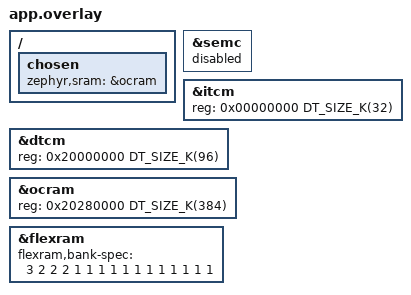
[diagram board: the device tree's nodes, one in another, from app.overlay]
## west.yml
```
manifest:
  remotes:
    - name: zephyrproject-rtos
      url-base: https://github.com/zephyrproject-rtos
  projects:
    - name: zephyr
      remote: zephyrproject-rtos
      revision: v4.4.2
      clone-depth: 1
      import: true
  self:
    path: app
```

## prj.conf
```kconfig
# Enable Zephyr Logging Framework
CONFIG_LOG=y
CONFIG_LOG_MODE_IMMEDIATE=n   # Use deferred logging mode for minimal performance impact

# Enable SEGGER RTT Core
CONFIG_USE_SEGGER_RTT=y
CONFIG_SEGGER_RTT_CUSTOM_LOCKING=y

CONFIG_LOG_BACKEND_RTT=n
CONFIG_LOG_BACKEND_UART=n    # Disable UART logging to save pins/power (optional)
CONFIG_SHELL_LOG_BACKEND=y

# Buffer size adjustments (increase if logs get dropped under high throughput)
CONFIG_SEGGER_RTT_BUFFER_SIZE_UP=2048
CONFIG_SHELL=y
CONFIG_SHELL_BACKEND_RTT=y

# Enable Zephyr's code & data relocation subsystem
# CONFIG_CODE_DATA_RELOCATION=y

# Enable Cortex-M7 instruction cache (ensures rest of XIP Flash runs at peak speed)
#CONFIG_ICACHE=y
#CONFIG_DCACHE=y

# Copy the ARM vector table into RAM (VTOR points to RAM)
# CONFIG_SRAM_VECTOR_TABLE=y

#CONFIG_SRAM_BASE_ADDRESS=0x20000000

CONFIG_GPIO=y

# (Optional) Enable thread names and kernel commands in the shell
CONFIG_THREAD_NAME=y
CONFIG_KERNEL_SHELL=y
CONFIG_DEVICE_SHELL=y

# Disable External SDRAM (SEMC) Controller
CONFIG_MEMC=n
CONFIG_INIT_STACKS=y

# Enable network stack
CONFIG_NETWORKING=y
CONFIG_NET_LOG=y

# Enable IPv4
CONFIG_NET_IPV4=y

# Enable IPv6
CONFIG_NET_IPV6=y

# Enable TCP
CONFIG_NET_TCP=y

# Enable DHCP
CONFIG_NET_DHCPV4=y

# Enable the hardware random number generator driver
CONFIG_ENTROPY_GENERATOR=y
CONFIG_ENTROPY_STM32_RNG=y

# Tell mbedTLS and the socket layer to use this entropy source
CONFIG_TEST_RANDOM_GENERATOR=n

#endable DNS

CONFIG_DNS_RESOLVER=y
CONFIG_DNS_RESOLVER_MAX_SERVERS=2
CONFIG_DNS_NUM_CONCUR_QUERIES=1

# Enable Sockets (used by MQTT lib)
CONFIG_NET_SOCKETS=y
CONFIG_NET_SOCKETS_SOCKOPT_TLS=y

# Enable MQTT
CONFIG_MQTT_LIB=y
CONFIG_MQTT_LIB_TLS=y

# Enable Mbed TLS
CONFIG_MBEDTLS=y
CONFIG_MBEDTLS_ENABLE_HEAP=y
CONFIG_MBEDTLS_HEAP_SIZE=60000
CONFIG_MBEDTLS_SSL_MAX_CONTENT_LEN=16384
CONFIG_MBEDTLS_PEM_PARSE_C=ya
CONFIG_MBEDTLS_PEM_WRITE_C=y
CONFIG_MBEDTLS_SSL_SERVER_NAME_INDICATION=y
CONFIG_MBEDTLS_CIPHERSUITE_TLS_ECDHE_RSA_WITH_AES_128_GCM_SHA256=y

# Enable JSON
CONFIG_JSON_LIBRARY=y

# Enable net conn manager
CONFIG_NET_CONNECTION_MANAGER=y

# Enable device hostname
CONFIG_NET_HOSTNAME_ENABLE=y

# Enable Posix API functionality
CONFIG_POSIX_API=y

# Enable sensor API
CONFIG_SENSOR=y

# Enable LED API
CONFIG_LED=y

# Main stack size
CONFIG_MAIN_STACK_SIZE=8196

# System work queue stack size
CONFIG_SYSTEM_WORKQUEUE_STACK_SIZE=4096

# Increase Rx net buffers
CONFIG_NET_BUF_RX_COUNT=100
```

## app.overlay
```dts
/ {
    chosen {
        /* Direct SRAM and system memory allocations to internal DTCM / OCRAM */
        zephyr,sram = &ocram;
    };
};

/* Explicitly disable the SEMC controller to turn off external SDRAM entirely */
&semc {
    status = "disabled";
};

/* Reconfigure FlexRAM bank mapping for 32KB ITCM, 96KB DTCM, 384KB OCRAM */
&itcm {
    reg = <0x00000000 DT_SIZE_K(32)>;
};

&dtcm {
    reg = <0x20000000 DT_SIZE_K(96)>;
};

&ocram {
    reg = <0x20280000 DT_SIZE_K(384)>;
};

&flexram {
    /*
     * Bank values: 1 = OCRAM, 2 = DTCM, 3 = ITCM
     * 16 total banks (32KB each)
     */
    flexram,bank-spec = <
        3                             /* Bank 0:  ITCM  (32 KB)  */
        2 2 2                         /* Banks 1-3: DTCM  (96 KB)  */
        1 1 1 1 1 1 1 1 1 1 1 1       /* Banks 4-15: OCRAM (384 KB) */
    >;
};
```

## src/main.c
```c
/*
 * Copyright (c) 2024 Analog Devices, Inc.
 *
 * SPDX-License-Identifier: Apache-2.0
 */

#include <zephyr/logging/log.h>
LOG_MODULE_REGISTER(app_main, LOG_LEVEL_DBG);

#include <zephyr/kernel.h>
#include <zephyr/drivers/gpio.h>
#include <zephyr/net/mqtt.h>
#include <zephyr/net/net_if.h>
#include <zephyr/net/net_mgmt.h>
#include <zephyr/net/conn_mgr_monitor.h>

#include "mqtt_client.h"
#include "device.h"

#define NET_L4_EVENT_MASK (NET_EVENT_L4_CONNECTED | NET_EVENT_L4_DISCONNECTED)

/* MQTT client struct */
static struct mqtt_client client_ctx;

/* MQTT publish work item */
struct k_work_delayable mqtt_publish_work;

static struct net_mgmt_event_callback net_l4_mgmt_cb;

/* Network connection semaphore */
K_SEM_DEFINE(net_conn_sem, 0, 1);

#define LED0_NODE DT_ALIAS(led0)

/* Retrieve the GPIO specification (controller device, pin number, flags) */
static const struct gpio_dt_spec led = GPIO_DT_SPEC_GET(LED0_NODE, gpios);

static void net_l4_evt_handler(struct net_mgmt_event_callback *cb,
				uint64_t mgmt_event, struct net_if *iface)
{
	switch (mgmt_event) {
	case NET_EVENT_L4_CONNECTED:
		k_sem_give(&net_conn_sem);
		LOG_INF("Network connectivity up!");
		break;
	case NET_EVENT_L4_DISCONNECTED:
		LOG_INF("Network connectivity down!");
		break;
	default:
		break;
	}
}

/** Print the device's MAC address to console */
void log_mac_addr(struct net_if *iface)
{
	struct net_linkaddr *mac;

	mac = net_if_get_link_addr(iface);

	LOG_INF("MAC Address: %02X:%02X:%02X:%02X:%02X:%02X",
		mac->addr[0], mac->addr[1], mac->addr[2],
		mac->addr[3], mac->addr[4], mac->addr[5]);
}

/** The system work queue is used to handle periodic MQTT publishing.
 *  Work queuing begins when the MQTT connection is established.
 *  Use CONFIG_NET_SAMPLE_MQTT_PUBLISH_INTERVAL to set the publish frequency.
 */

static void publish_work_handler(struct k_work *work)
{
	int rc;

	if (mqtt_connected) {
		rc = app_mqtt_publish(&client_ctx);
		if (rc != 0) {
			LOG_INF("MQTT Publish failed [%d]", rc);
		}
		k_work_reschedule(&mqtt_publish_work,
					K_SECONDS(CONFIG_NET_SAMPLE_MQTT_PUBLISH_INTERVAL));
	} else {
		k_work_cancel_delayable(&mqtt_publish_work);
	}
}

int main(void)
{
	int rc;
	struct net_if *iface;

	devices_ready();

/* Verify that the GPIO device driver is ready */
    if (!gpio_is_ready_dt(&led)) {
        LOG_ERR("Error: GPIO device %s is not ready", led.port->name);
        return 0;
    }

    /* Configure the pin as an output, initializing it to active (LED ON) */
    rc = gpio_pin_configure_dt(&led, GPIO_OUTPUT_ACTIVE);
    if (rc < 0) {
        LOG_ERR("Error %d: Failed to configure GPIO pin", rc);
        return 0;
    }

    gpio_pin_set_dt(&led, 1);

	iface = net_if_get_default();
	if (iface == NULL) {
		LOG_ERR("No network interface configured");
		return -ENETDOWN;
	}

	log_mac_addr(iface);

	/* Register callbacks for L4 events */
	net_mgmt_init_event_callback(&net_l4_mgmt_cb, &net_l4_evt_handler, NET_L4_EVENT_MASK);
	net_mgmt_add_event_callback(&net_l4_mgmt_cb);

	LOG_INF("Bringing up network..");

#if defined(CONFIG_NET_DHCPV4)
	net_dhcpv4_start(iface);
#else
	/* If using static IP, L4 Connect callback will happen,
	 * before conn mgr is initialised, so resend events here
	 * to check for connectivity
	 */
	conn_mgr_mon_resend_status();
#endif

	/* Wait for network to come up */
	while (k_sem_take(&net_conn_sem, K_MSEC(MSECS_NET_POLL_TIMEOUT)) != 0) {
		LOG_INF("Waiting for network connection..");
	}

	rc = app_mqtt_init(&client_ctx);
	if (rc != 0) {
		LOG_ERR("MQTT Init failed [%d]", rc);
		return rc;
	}

	/* Initialise MQTT publish work item */
	k_work_init_delayable(&mqtt_publish_work, publish_work_handler);

	/* Thread main loop */
	while (1) {
		/* Block until MQTT connection is up */
		app_mqtt_connect(&client_ctx);

		/* We are now connected, begin queueing periodic MQTT publishes */
		k_work_reschedule(&mqtt_publish_work,
					K_SECONDS(CONFIG_NET_SAMPLE_MQTT_PUBLISH_INTERVAL));

		/* Handle MQTT inputs and connection */
		app_mqtt_run(&client_ctx);
	}

	return rc;
}
```
